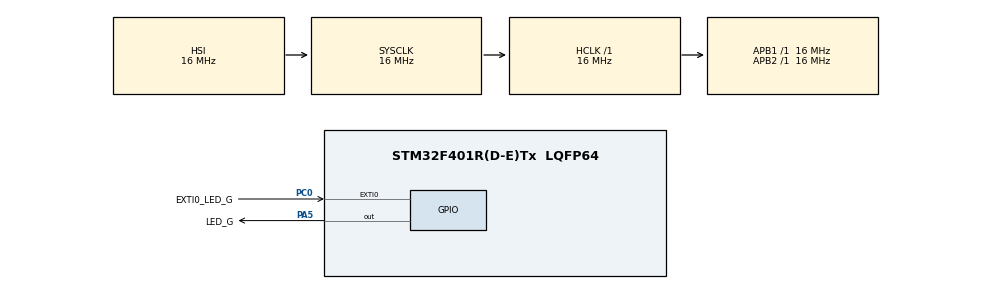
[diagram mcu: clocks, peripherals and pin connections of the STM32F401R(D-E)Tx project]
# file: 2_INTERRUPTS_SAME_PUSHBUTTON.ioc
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Mcu.Family=STM32F4
RCC.CortexFreq_Value=16000000
PC0.GPIO_Label=EXTI0_LED_G
PC0.Signal=GPXTI0
ProjectManager.StackSize=0x400
PA13.Signal=SYS_JTMS-SWDIO
ProjectManager.TargetToolchain=STM32CubeIDE
RCC.LSE_VALUE=32768
RCC.AHBFreq_Value=16000000
PA5.Signal=GPIO_Output
RCC.HSE_VALUE=25000000
board=custom
RCC.VCOOutputFreq_Value=192000000
RCC.APB2Freq_Value=16000000
PA14.Mode=Serial_Wire
PA13.Mode=Serial_Wire
Mcu.Name=STM32F401R(D-E)Tx
PC0.GPIO_ModeDefaultEXTI=GPIO_MODE_IT_RISING_FALLING
NVIC.EXTI0_IRQn=true\:0\:0\:false\:false\:true\:true\:true
RCC.SYSCLKFreq_VALUE=16000000
Mcu.Package=LQFP64
PA5.GPIO_Label=LED_G
PA14.Signal=SYS_JTCK-SWCLK
ProjectManager.HeapSize=0x200
RCC.HSI_VALUE=16000000
NVIC.PriorityGroup=NVIC_PRIORITYGROUP_4
PC0.GPIO_PuPd=GPIO_PULLUP
RCC.APB1Freq_Value=16000000

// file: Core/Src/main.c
/* USER CODE BEGIN Header */
/**
 *
 * EXCERCESE
 *     Two interrupts with the same button (rising/falling edge).
	   Two ISR to toggle the led2 of the Nucleo board.
 *
  ******************************************************************************
  * @file           : main.c
  * @brief          : Main program body
  ******************************************************************************
  * @attention
  *
  * <h2><center>&copy; Copyright (c) 2021 STMicroelectronics.
  * All rights reserved.</center></h2>
  *
  * This software component is licensed by ST under BSD 3-Clause license,
  * the "License"; You may not use this file except in compliance with the
  * License. You may obtain a copy of the License at:
  *                        opensource.org/licenses/BSD-3-Clause
  *
  ******************************************************************************
  */
/* USER CODE END Header */
#include "main.h"
#include "gpio.h"

void SystemClock_Config(void);

/* USER CODE BEGIN 0 */
void HAL_GPIO_EXTI_Callback(uint16_t GPIO_Pin)
{
	//Condition to check if the interruption was generated by a falling edge.
	//Note: falling edge is generated when we press the button (mode pull up)
	//ISR_1 BEGGIN
	if(HAL_GPIO_ReadPin(EXTI0_LED_G_GPIO_Port, EXTI0_LED_G_Pin) == GPIO_PIN_RESET )
	{
		HAL_GPIO_TogglePin(LED_G_GPIO_Port, LED_G_Pin);
	}
	// ISR_1 END
	//ISR_2 BEGGIN
	//If the interruption was not generated by the falling edge so it was generated by the rising edge
	else
	{
		HAL_GPIO_TogglePin(LED_G_GPIO_Port, LED_G_Pin);
	}
	//ISR_2 END

}
/* USER CODE END 0 */

int main(void)
{

  /* MCU Configuration--------------------------------------------------------*/

  /* Reset of all peripherals, Initializes the Flash interface and the Systick. */
  HAL_Init();

  /* Configure the system clock */
  SystemClock_Config();

  /* Initialize all configured peripherals */
  MX_GPIO_Init();

  /* Infinite loop */
  while (1)
  {

  }
}

void SystemClock_Config(void)
{
  RCC_OscInitTypeDef RCC_OscInitStruct = {0};
  RCC_ClkInitTypeDef RCC_ClkInitStruct = {0};

  /** Configure the main internal regulator output voltage
  */
  __HAL_RCC_PWR_CLK_ENABLE();
  __HAL_PWR_VOLTAGESCALING_CONFIG(PWR_REGULATOR_VOLTAGE_SCALE2);
  /** Initializes the RCC Oscillators according to the specified parameters
  * in the RCC_OscInitTypeDef structure.
  */
  RCC_OscInitStruct.OscillatorType = RCC_OSCILLATORTYPE_HSI;
  RCC_OscInitStruct.HSIState = RCC_HSI_ON;
  RCC_OscInitStruct.HSICalibrationValue = RCC_HSICALIBRATION_DEFAULT;
  RCC_OscInitStruct.PLL.PLLState = RCC_PLL_NONE;
  if (HAL_RCC_OscConfig(&RCC_OscInitStruct) != HAL_OK)
  {
    Error_Handler();
  }
  /** Initializes the CPU, AHB and APB buses clocks
  */
  RCC_ClkInitStruct.ClockType = RCC_CLOCKTYPE_HCLK|RCC_CLOCKTYPE_SYSCLK
                              |RCC_CLOCKTYPE_PCLK1|RCC_CLOCKTYPE_PCLK2;
  RCC_ClkInitStruct.SYSCLKSource = RCC_SYSCLKSOURCE_HSI;
  RCC_ClkInitStruct.AHBCLKDivider = RCC_SYSCLK_DIV1;
  RCC_ClkInitStruct.APB1CLKDivider = RCC_HCLK_DIV1;
  RCC_ClkInitStruct.APB2CLKDivider = RCC_HCLK_DIV1;

  if (HAL_RCC_ClockConfig(&RCC_ClkInitStruct, FLASH_LATENCY_0) != HAL_OK)
  {
    Error_Handler();
  }
}

void Error_Handler(void)
{
  __disable_irq();
  while (1)
  {
  }
}

/************************ (C) COPYRIGHT STMicroelectronics *****END OF FILE****/
